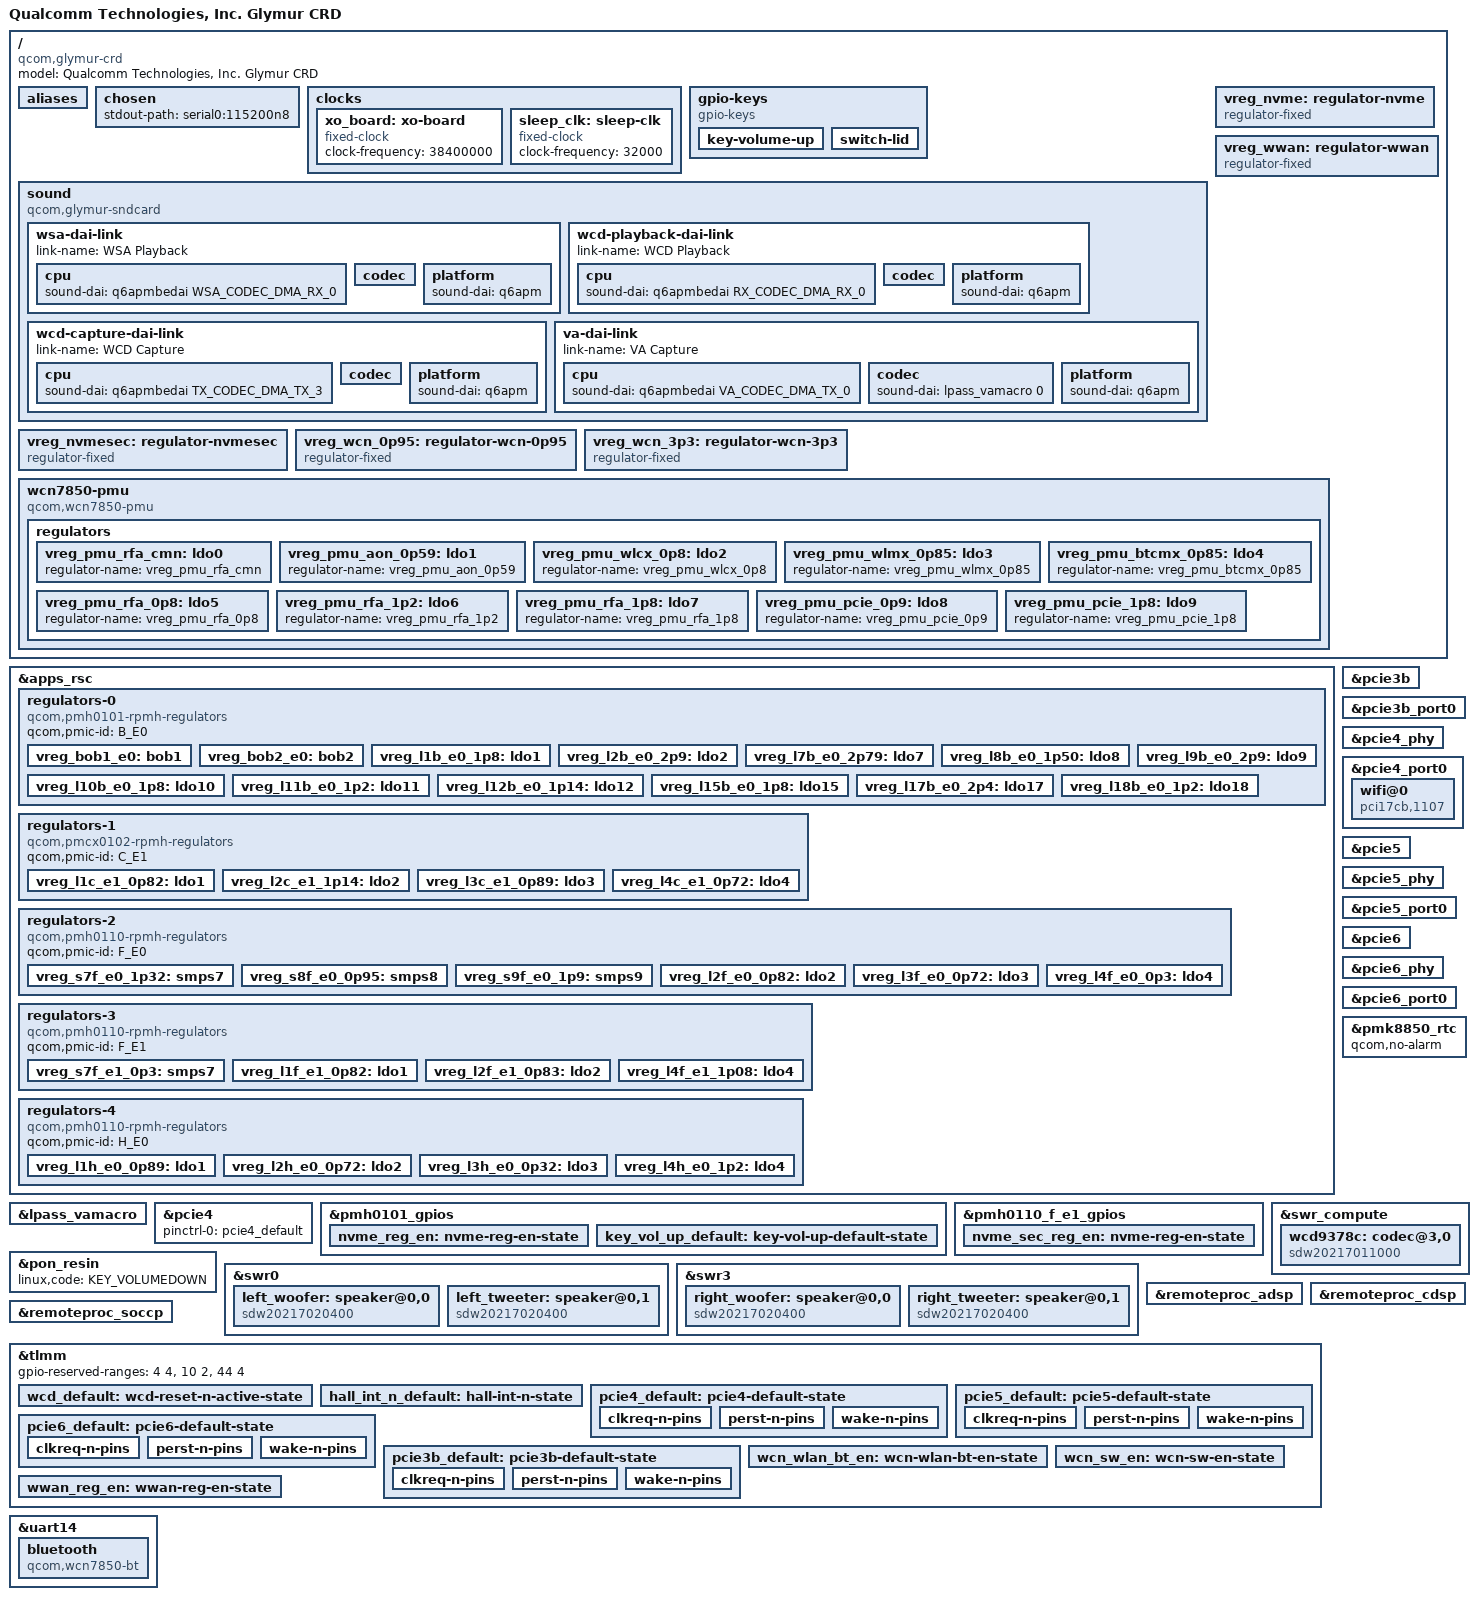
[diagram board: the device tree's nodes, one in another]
// SPDX-License-Identifier: BSD-3-Clause
/*
 * Copyright (c) Qualcomm Technologies, Inc. and/or its subsidiaries.
 */

#include "pmcx0102.dtsi"        /* SPMI0: SID-2/3 SPMI1: SID-2/3 */
#include "pmh0101.dtsi"         /* SPMI0: SID-1                  */
#include "pmh0110-glymur.dtsi"  /* SPMI0: SID-5/7 SPMI1: SID-5   */
#include "pmh0104-glymur.dtsi"  /* SPMI0: SID-8/9 SPMI1: SID-11  */
#include "pmk8850.dtsi"         /* SPMI0: SID-0                  */
#include "smb2370.dtsi"         /* SPMI2: SID-9/10/11            */

#include <dt-bindings/input/gpio-keys.h>

/ {
	model = "Qualcomm Technologies, Inc. Glymur CRD";
	compatible = "qcom,glymur-crd", "qcom,glymur";

	aliases {
		serial0 = &uart21;
		serial1 = &uart14;
		i2c0 = &i2c0;
		i2c1 = &i2c4;
		i2c2 = &i2c5;
		spi0 = &spi18;
	};

	chosen {
		stdout-path = "serial0:115200n8";
	};

	clocks {
		xo_board: xo-board {
			compatible = "fixed-clock";
			clock-frequency = <38400000>;
			#clock-cells = <0>;
		};

		sleep_clk: sleep-clk {
			compatible = "fixed-clock";
			clock-frequency = <32000>;
			#clock-cells = <0>;
		};
	};

	gpio-keys {
		compatible = "gpio-keys";

		pinctrl-0 = <&key_vol_up_default>, <&hall_int_n_default>;
		pinctrl-names = "default";

		key-volume-up {
			label = "Volume Up";
			linux,code = <KEY_VOLUMEUP>;
			gpios = <&pmh0101_gpios 6 GPIO_ACTIVE_LOW>;
			debounce-interval = <15>;
			linux,can-disable;
			wakeup-source;
		};

		switch-lid {
			label = "lid";
			gpios = <&tlmm 92 GPIO_ACTIVE_LOW>;
			linux,input-type = <EV_SW>;
			linux,code = <SW_LID>;
			wakeup-source;
			wakeup-event-action = <EV_ACT_DEASSERTED>;
		};
	};

	sound {
		compatible = "qcom,glymur-sndcard";
		model = "GLYMUR-CRD";
		audio-routing = "WooferLeft IN", "WSA WSA_SPK1 OUT",
				"TweeterLeft IN", "WSA WSA_SPK2 OUT",
				"WooferRight IN", "WSA2 WSA_SPK1 OUT",
				"TweeterRight IN", "WSA2 WSA_SPK2 OUT",
				"VA DMIC0", "vdd-micb",
				"VA DMIC1", "vdd-micb",
				"VA DMIC2", "vdd-micb",
				"VA DMIC3", "vdd-micb",
				"IT 41 Playback", "HPHL_OUT",
				"IT 41 Playback", "HPHR_OUT",
				/*
				 * Bridge the TX macro SoundWire input to the
				 * WCD9378 capture output terminal (OT 36, DP2)
				 * so DAPM completes the codec->macro capture
				 * path.  Without this the macro powers its
				 * decimator but no data is pulled from the codec.
				 */
				"TX SWR_INPUT1", "OT 36 Capture";

		wsa-dai-link {
			link-name = "WSA Playback";

			cpu {
				sound-dai = <&q6apmbedai WSA_CODEC_DMA_RX_0>;
			};

			codec {
				sound-dai = <&left_woofer>, <&left_tweeter>,
					    <&swr0 0>, <&lpass_wsamacro 0>,
					    <&right_woofer>, <&right_tweeter>,
					    <&swr3 0>, <&lpass_wsa2macro 0>;
			};

			platform {
				sound-dai = <&q6apm>;
			};
		};
		/*
		 * Compute mode: swr_compute is the single multi-lane SoundWire
		 * master; ASoC needs its master DAI in the codec cell so port
		 * setup and stream_add_master are driven for both banks.
		 *   swr_compute pin 0 = dout (playback)
		 *   swr_compute pin 1 = din  (capture)
		 */
		wcd-playback-dai-link {
			link-name = "WCD Playback";

			cpu {
				sound-dai = <&q6apmbedai RX_CODEC_DMA_RX_0>;
			};

			codec {
				sound-dai = <&wcd9378c 0>, <&swr_compute 0>, <&lpass_rxmacro 0>;
			};

			platform {
				sound-dai = <&q6apm>;
			};
		};

		wcd-capture-dai-link {
			link-name = "WCD Capture";

			cpu {
				sound-dai = <&q6apmbedai TX_CODEC_DMA_TX_3>;
			};

			codec {
				sound-dai = <&wcd9378c 18>, <&swr_compute 1>, <&lpass_txmacro 0>;
			};

			platform {
				sound-dai = <&q6apm>;
			};
		};

		va-dai-link {
			link-name = "VA Capture";

			cpu {
				sound-dai = <&q6apmbedai VA_CODEC_DMA_TX_0>;
			};

			codec {
				sound-dai = <&lpass_vamacro 0>;
			};

			platform {
				sound-dai = <&q6apm>;
			};
		};
	};

	vreg_nvme: regulator-nvme {
		compatible = "regulator-fixed";

		regulator-name = "VREG_NVME_3P3";
		regulator-min-microvolt = <3300000>;
		regulator-max-microvolt = <3300000>;

		gpio = <&pmh0101_gpios 14 GPIO_ACTIVE_HIGH>;
		enable-active-high;

		pinctrl-0 = <&nvme_reg_en>;
		pinctrl-names = "default";

		regulator-boot-on;
	};

	vreg_nvmesec: regulator-nvmesec {
		compatible = "regulator-fixed";

		regulator-name = "VREG_NVME_SEC_3P3";
		regulator-min-microvolt = <3300000>;
		regulator-max-microvolt = <3300000>;

		gpio = <&pmh0110_f_e1_gpios 14 GPIO_ACTIVE_HIGH>;
		enable-active-high;

		pinctrl-0 = <&nvme_sec_reg_en>;
		pinctrl-names = "default";

		regulator-boot-on;
	};

	vreg_wcn_0p95: regulator-wcn-0p95 {
		compatible = "regulator-fixed";

		regulator-name = "VREG_WCN_0P95";
		regulator-min-microvolt = <950000>;
		regulator-max-microvolt = <950000>;

		vin-supply = <&vreg_wcn_3p3>;
	};

	vreg_wcn_3p3: regulator-wcn-3p3 {
		compatible = "regulator-fixed";

		regulator-name = "VREG_WCN_3P3";
		regulator-min-microvolt = <3300000>;
		regulator-max-microvolt = <3300000>;

		gpio = <&tlmm 94 GPIO_ACTIVE_HIGH>;
		enable-active-high;

		pinctrl-0 = <&wcn_sw_en>;
		pinctrl-names = "default";

		regulator-boot-on;
	};

	vreg_wwan: regulator-wwan {
		compatible = "regulator-fixed";

		regulator-name = "VREG_WWAN_3P3";
		regulator-min-microvolt = <3300000>;
		regulator-max-microvolt = <3300000>;

		gpio = <&tlmm 246 GPIO_ACTIVE_HIGH>;
		enable-active-high;

		pinctrl-0 = <&wwan_reg_en>;
		pinctrl-names = "default";
	};

	wcn7850-pmu {
		compatible = "qcom,wcn7850-pmu";

		vdd-supply = <&vreg_wcn_0p95>;
		vddio-supply = <&vreg_l15b_e0_1p8>;
		vddaon-supply = <&vreg_l15b_e0_1p8>;
		vdddig-supply = <&vreg_l15b_e0_1p8>;
		vddrfa1p2-supply = <&vreg_l15b_e0_1p8>;
		vddrfa1p8-supply = <&vreg_l15b_e0_1p8>;

		wlan-enable-gpios = <&tlmm 117 GPIO_ACTIVE_HIGH>;
		bt-enable-gpios = <&tlmm 116 GPIO_ACTIVE_HIGH>;

		pinctrl-0 = <&wcn_wlan_bt_en>;
		pinctrl-names = "default";

		regulators {
			vreg_pmu_rfa_cmn: ldo0 {
				regulator-name = "vreg_pmu_rfa_cmn";
			};

			vreg_pmu_aon_0p59: ldo1 {
				regulator-name = "vreg_pmu_aon_0p59";
			};

			vreg_pmu_wlcx_0p8: ldo2 {
				regulator-name = "vreg_pmu_wlcx_0p8";
			};

			vreg_pmu_wlmx_0p85: ldo3 {
				regulator-name = "vreg_pmu_wlmx_0p85";
			};

			vreg_pmu_btcmx_0p85: ldo4 {
				regulator-name = "vreg_pmu_btcmx_0p85";
			};

			vreg_pmu_rfa_0p8: ldo5 {
				regulator-name = "vreg_pmu_rfa_0p8";
			};

			vreg_pmu_rfa_1p2: ldo6 {
				regulator-name = "vreg_pmu_rfa_1p2";
			};

			vreg_pmu_rfa_1p8: ldo7 {
				regulator-name = "vreg_pmu_rfa_1p8";
			};

			vreg_pmu_pcie_0p9: ldo8 {
				regulator-name = "vreg_pmu_pcie_0p9";
			};

			vreg_pmu_pcie_1p8: ldo9 {
				regulator-name = "vreg_pmu_pcie_1p8";
			};
		};
	};
};

&apps_rsc {
	regulators-0 {
		compatible = "qcom,pmh0101-rpmh-regulators";
		qcom,pmic-id = "B_E0";

		vreg_bob1_e0: bob1 {
			regulator-name = "vreg_bob1_e0";
			regulator-min-microvolt = <2200000>;
			regulator-max-microvolt = <4224000>;
			regulator-initial-mode = <RPMH_REGULATOR_MODE_AUTO>;
		};

		vreg_bob2_e0: bob2 {
			regulator-name = "vreg_bob2_e0";
			regulator-min-microvolt = <2540000>;
			regulator-max-microvolt = <3600000>;
			regulator-initial-mode = <RPMH_REGULATOR_MODE_AUTO>;
		};

		vreg_l1b_e0_1p8: ldo1 {
			regulator-name = "vreg_l1b_e0_1p8";
			regulator-min-microvolt = <1800000>;
			regulator-max-microvolt = <1800000>;
			regulator-initial-mode = <RPMH_REGULATOR_MODE_HPM>;
		};

		vreg_l2b_e0_2p9: ldo2 {
			regulator-name = "vreg_l2b_e0_2p9";
			regulator-min-microvolt = <1804000>;
			regulator-max-microvolt = <2904000>;
			regulator-initial-mode = <RPMH_REGULATOR_MODE_HPM>;
		};

		vreg_l7b_e0_2p79: ldo7 {
			regulator-name = "vreg_l7b_e0_2p79";
			regulator-min-microvolt = <2790000>;
			regulator-max-microvolt = <2792000>;
			regulator-initial-mode = <RPMH_REGULATOR_MODE_HPM>;
		};

		vreg_l8b_e0_1p50: ldo8 {
			regulator-name = "vreg_l8b_e0_1p50";
			regulator-min-microvolt = <1504000>;
			regulator-max-microvolt = <1504000>;
			regulator-initial-mode = <RPMH_REGULATOR_MODE_HPM>;
		};

		vreg_l9b_e0_2p9: ldo9 {
			regulator-name = "vreg_l9b_e0_2p9";
			regulator-min-microvolt = <2960000>;
			regulator-max-microvolt = <2960000>;
			regulator-initial-mode = <RPMH_REGULATOR_MODE_HPM>;
		};

		vreg_l10b_e0_1p8: ldo10 {
			regulator-name = "vreg_l10b_e0_1p8";
			regulator-min-microvolt = <1800000>;
			regulator-max-microvolt = <1800000>;
			regulator-initial-mode = <RPMH_REGULATOR_MODE_HPM>;
		};

		vreg_l11b_e0_1p2: ldo11 {
			regulator-name = "vreg_l11b_e0_1p2";
			regulator-min-microvolt = <1200000>;
			regulator-max-microvolt = <1200000>;
			regulator-initial-mode = <RPMH_REGULATOR_MODE_HPM>;
		};

		vreg_l12b_e0_1p14: ldo12 {
			regulator-name = "vreg_l12b_e0_1p14";
			regulator-min-microvolt = <1144000>;
			regulator-max-microvolt = <1144000>;
			regulator-initial-mode = <RPMH_REGULATOR_MODE_HPM>;
		};

		vreg_l15b_e0_1p8: ldo15 {
			regulator-name = "vreg_l15b_e0_1p8";
			regulator-min-microvolt = <1800000>;
			regulator-max-microvolt = <1800000>;
			regulator-initial-mode = <RPMH_REGULATOR_MODE_HPM>;
		};

		vreg_l17b_e0_2p4: ldo17 {
			regulator-name = "vreg_l17b_e0_2p4";
			regulator-min-microvolt = <2400000>;
			regulator-max-microvolt = <2700000>;
			regulator-initial-mode = <RPMH_REGULATOR_MODE_HPM>;
		};

		vreg_l18b_e0_1p2: ldo18 {
			regulator-name = "vreg_l18b_e0_1p2";
			regulator-min-microvolt = <1200000>;
			regulator-max-microvolt = <1200000>;
			regulator-initial-mode = <RPMH_REGULATOR_MODE_HPM>;
		};
	};

	regulators-1 {
		compatible = "qcom,pmcx0102-rpmh-regulators";
		qcom,pmic-id = "C_E1";

		vreg_l1c_e1_0p82: ldo1 {
			regulator-name = "vreg_l1c_e1_0p82";
			regulator-min-microvolt = <832000>;
			regulator-max-microvolt = <832000>;
			regulator-initial-mode = <RPMH_REGULATOR_MODE_HPM>;
		};

		vreg_l2c_e1_1p14: ldo2 {
			regulator-name = "vreg_l2c_e1_1p14";
			regulator-min-microvolt = <1144000>;
			regulator-max-microvolt = <1144000>;
			regulator-initial-mode = <RPMH_REGULATOR_MODE_HPM>;
		};

		vreg_l3c_e1_0p89: ldo3 {
			regulator-name = "vreg_l3c_e1_0p89";
			regulator-min-microvolt = <890000>;
			regulator-max-microvolt = <980000>;
			regulator-initial-mode = <RPMH_REGULATOR_MODE_HPM>;
		};

		vreg_l4c_e1_0p72: ldo4 {
			regulator-name = "vreg_l4c_e1_0p72";
			regulator-min-microvolt = <720000>;
			regulator-max-microvolt = <720000>;
			regulator-initial-mode = <RPMH_REGULATOR_MODE_HPM>;
		};
	};

	regulators-2 {
		compatible = "qcom,pmh0110-rpmh-regulators";
		qcom,pmic-id = "F_E0";

		vreg_s7f_e0_1p32: smps7 {
			regulator-name = "vreg_s7f_e0_1p32";
			regulator-min-microvolt = <1320000>;
			regulator-max-microvolt = <1352000>;
			regulator-initial-mode = <RPMH_REGULATOR_MODE_HPM>;
		};

		vreg_s8f_e0_0p95: smps8 {
			regulator-name = "vreg_s8f_e0_0p95";
			regulator-min-microvolt = <952000>;
			regulator-max-microvolt = <1200000>;
			regulator-initial-mode = <RPMH_REGULATOR_MODE_HPM>;
		};

		vreg_s9f_e0_1p9: smps9 {
			regulator-name = "vreg_s9f_e0_1p9";
			regulator-min-microvolt = <1900000>;
			regulator-max-microvolt = <2000000>;
			regulator-initial-mode = <RPMH_REGULATOR_MODE_HPM>;
		};

		vreg_l2f_e0_0p82: ldo2 {
			regulator-name = "vreg_l2f_e0_0p82";
			regulator-min-microvolt = <832000>;
			regulator-max-microvolt = <832000>;
			regulator-initial-mode = <RPMH_REGULATOR_MODE_HPM>;
		};

		vreg_l3f_e0_0p72: ldo3 {
			regulator-name = "vreg_l3f_e0_0p72";
			regulator-min-microvolt = <720000>;
			regulator-max-microvolt = <720000>;
			regulator-initial-mode = <RPMH_REGULATOR_MODE_HPM>;
		};

		vreg_l4f_e0_0p3: ldo4 {
			regulator-name = "vreg_l4f_e0_0p3";
			regulator-min-microvolt = <1080000>;
			regulator-max-microvolt = <1200000>;
			regulator-initial-mode = <RPMH_REGULATOR_MODE_HPM>;
		};
	};

	regulators-3 {
		compatible = "qcom,pmh0110-rpmh-regulators";
		qcom,pmic-id = "F_E1";

		vreg_s7f_e1_0p3: smps7 {
			regulator-name = "vreg_s7f_e1_0p3";
			regulator-min-microvolt = <300000>;
			regulator-max-microvolt = <1200000>;
			regulator-initial-mode = <RPMH_REGULATOR_MODE_HPM>;
		};

		vreg_l1f_e1_0p82: ldo1 {
			regulator-name = "vreg_l1f_e1_0p82";
			regulator-min-microvolt = <832000>;
			regulator-max-microvolt = <832000>;
			regulator-initial-mode = <RPMH_REGULATOR_MODE_HPM>;
		};

		vreg_l2f_e1_0p83: ldo2 {
			regulator-name = "vreg_l2f_e1_0p83";
			regulator-min-microvolt = <832000>;
			regulator-max-microvolt = <832000>;
			regulator-initial-mode = <RPMH_REGULATOR_MODE_HPM>;
		};

		vreg_l4f_e1_1p08: ldo4 {
			regulator-name = "vreg_l4f_e1_1p08";
			regulator-min-microvolt = <1080000>;
			regulator-max-microvolt = <1320000>;
			regulator-initial-mode = <RPMH_REGULATOR_MODE_HPM>;
		};
	};

	regulators-4 {
		compatible = "qcom,pmh0110-rpmh-regulators";
		qcom,pmic-id = "H_E0";

		vreg_l1h_e0_0p89: ldo1 {
			regulator-name = "vreg_l1h_e0_0p89";
			regulator-min-microvolt = <832000>;
			regulator-max-microvolt = <832000>;
			regulator-initial-mode = <RPMH_REGULATOR_MODE_HPM>;
		};

		vreg_l2h_e0_0p72: ldo2 {
			regulator-name = "vreg_l2h_e0_0p72";
			regulator-min-microvolt = <832000>;
			regulator-max-microvolt = <832000>;
			regulator-initial-mode = <RPMH_REGULATOR_MODE_HPM>;
		};

		vreg_l3h_e0_0p32: ldo3 {
			regulator-name = "vreg_l3h_e0_0p32";
			regulator-min-microvolt = <320000>;
			regulator-max-microvolt = <2000000>;
			regulator-initial-mode = <RPMH_REGULATOR_MODE_HPM>;
		};

		vreg_l4h_e0_1p2: ldo4 {
			regulator-name = "vreg_l4h_e0_1p2";
			regulator-min-microvolt = <1080000>;
			regulator-max-microvolt = <1320000>;
			regulator-initial-mode = <RPMH_REGULATOR_MODE_HPM>;
		};
	};
};

&lpass_vamacro {
	pinctrl-0 = <&dmic01_default>, <&dmic23_default>;
	pinctrl-names = "default";
	qcom,dmic-sample-rate = <4800000>;
};

&pcie3b {
	vddpe-3v3-supply = <&vreg_nvmesec>;

	pinctrl-0 = <&pcie3b_default>;
	pinctrl-names = "default";
};

&pcie3b_port0 {
	reset-gpios = <&tlmm 155 GPIO_ACTIVE_LOW>;
	wake-gpios = <&tlmm 157 GPIO_ACTIVE_LOW>;
};

&pcie4 {
	pinctrl-0 = <&pcie4_default>;
	pinctrl-names = "default";

	status = "okay";
};

&pcie4_phy {
	vdda-phy-supply = <&vreg_l1c_e1_0p82>;
	vdda-pll-supply = <&vreg_l4f_e1_1p08>;

	status = "okay";
};

&pcie4_port0 {
	reset-gpios = <&tlmm 146 GPIO_ACTIVE_LOW>;
	wake-gpios = <&tlmm 148 GPIO_ACTIVE_LOW>;

	wifi@0 {
		compatible = "pci17cb,1107";
		reg = <0x10000 0x0 0x0 0x0 0x0>;

		vddaon-supply = <&vreg_pmu_aon_0p59>;
		vddwlcx-supply = <&vreg_pmu_wlcx_0p8>;
		vddwlmx-supply = <&vreg_pmu_wlmx_0p85>;
		vddrfacmn-supply = <&vreg_pmu_rfa_cmn>;
		vddrfa0p8-supply = <&vreg_pmu_rfa_0p8>;
		vddrfa1p2-supply = <&vreg_pmu_rfa_1p2>;
		vddrfa1p8-supply = <&vreg_pmu_rfa_1p8>;
		vddpcie0p9-supply = <&vreg_pmu_pcie_0p9>;
		vddpcie1p8-supply = <&vreg_pmu_pcie_1p8>;
	};
};

&pcie5 {
	vddpe-3v3-supply = <&vreg_nvme>;

	pinctrl-0 = <&pcie5_default>;
	pinctrl-names = "default";

	status = "okay";
};

&pcie5_phy {
	vdda-phy-supply = <&vreg_l2f_e0_0p82>;
	vdda-pll-supply = <&vreg_l4h_e0_1p2>;

	status = "okay";
};

&pcie5_port0 {
	reset-gpios = <&tlmm 152 GPIO_ACTIVE_LOW>;
	wake-gpios = <&tlmm 154 GPIO_ACTIVE_LOW>;
};

&pcie6 {
	vddpe-3v3-supply = <&vreg_wwan>;

	pinctrl-0 = <&pcie6_default>;
	pinctrl-names = "default";

	status = "okay";
};

&pcie6_phy {
	vdda-phy-supply = <&vreg_l1c_e1_0p82>;
	vdda-pll-supply = <&vreg_l4f_e1_1p08>;

	status = "okay";
};

&pcie6_port0 {
	reset-gpios = <&tlmm 149 GPIO_ACTIVE_LOW>;
	wake-gpios = <&tlmm 151 GPIO_ACTIVE_LOW>;
};

&pmh0101_gpios {
	nvme_reg_en: nvme-reg-en-state {
		pins = "gpio14";
		function = "normal";
		bias-disable;
	};

	key_vol_up_default: key-vol-up-default-state {
		pins = "gpio6";
		function = "normal";
		output-disable;
		bias-pull-up;
	};
};

&pmh0110_f_e1_gpios {
	nvme_sec_reg_en: nvme-reg-en-state {
		pins = "gpio14";
		function = "normal";
		bias-disable;
	};
};

&pmk8850_rtc {
	qcom,no-alarm;
};

&pon_resin {
	linux,code = <KEY_VOLUMEDOWN>;
	status = "okay";
};

&swr0 {
	status = "okay";

	/* WSA8845, Left Woofer */
	left_woofer: speaker@0,0 {
		compatible = "sdw20217020400";
		reg = <0 0>;
		reset-gpios = <&lpass_tlmm 12 GPIO_ACTIVE_LOW>;
		#sound-dai-cells = <0>;
		sound-name-prefix = "WooferLeft";
		vdd-1p8-supply = <&vreg_l15b_e0_1p8>;
		vdd-io-supply = <&vreg_l18b_e0_1p2>;
		qcom,port-mapping = <1 2 3 7 12 14>;
	};

	/* WSA8845, Left Tweeter */
	left_tweeter: speaker@0,1 {
		compatible = "sdw20217020400";
		reg = <0 1>;
		reset-gpios = <&lpass_tlmm 12 GPIO_ACTIVE_LOW>;
		#sound-dai-cells = <0>;
		sound-name-prefix = "TweeterLeft";
		vdd-1p8-supply = <&vreg_l15b_e0_1p8>;
		vdd-io-supply = <&vreg_l18b_e0_1p2>;
		qcom,port-mapping = <4 5 6 7 13 15>;
	};
};
/*
 * Glymur runs WCD9378 in SDCA compute mode: one slave on one logical
 * SoundWire bus that aggregates the TX and RX SWR master IPs.  Use the
 * multi-lane controller (swr_compute) instead of the per-IP swr1/swr2,
 * which therefore stay disabled (default).
 */
&swr_compute {
	status = "okay";

	wcd9378c: codec@3,0 {
		compatible = "sdw20217011000";
		reg = <0 3>;

		pinctrl-names = "default";
		pinctrl-0 = <&wcd_default>;

		reset-gpios = <&tlmm 191 GPIO_ACTIVE_LOW>;

		vdd-buck-supply = <&vreg_l15b_e0_1p8>;
		vdd-rxtx-supply = <&vreg_l15b_e0_1p8>;
		vdd-io-supply = <&vreg_l18b_e0_1p2>;
		vdd-mic-bias-supply = <&vreg_bob1_e0>;

		#sound-dai-cells = <1>;
		/* DP1..DP8 → unified bus ports (lanes select the bank).
		 * Ports 2 (DP2 TX), 6/7/8 (DP6/7/8 RX) drive real traffic. */
		qcom,port-mapping = <2 2 3 4 5 6 7 8>;
	};
};


&swr3 {
	status = "okay";

	/* WSA8845, Right Woofer */
	right_woofer: speaker@0,0 {
		compatible = "sdw20217020400";
		reg = <0 0>;
		reset-gpios = <&lpass_tlmm 13 GPIO_ACTIVE_LOW>;
		#sound-dai-cells = <0>;
		sound-name-prefix = "WooferRight";
		vdd-1p8-supply = <&vreg_l15b_e0_1p8>;
		vdd-io-supply = <&vreg_l18b_e0_1p2>;
		qcom,port-mapping = <1 2 3 7 12 14>;
	};

	/* WSA8845, Right Tweeter */
	right_tweeter: speaker@0,1 {
		compatible = "sdw20217020400";
		reg = <0 1>;
		reset-gpios = <&lpass_tlmm 13 GPIO_ACTIVE_LOW>;
		#sound-dai-cells = <0>;
		sound-name-prefix = "TweeterRight";
		vdd-1p8-supply = <&vreg_l15b_e0_1p8>;
		vdd-io-supply = <&vreg_l18b_e0_1p2>;
		qcom,port-mapping = <4 5 6 7 13 15>;
	};
};

&remoteproc_adsp {
	firmware-name = "qcom/glymur/adsp.mbn",
			"qcom/glymur/adsp_dtb.mbn";

	status = "okay";
};

&remoteproc_cdsp {
	firmware-name = "qcom/glymur/cdsp.mbn",
			"qcom/glymur/cdsp_dtb.mbn";

	status = "okay";
};

&remoteproc_soccp {
	status = "okay";
};

&tlmm {
	gpio-reserved-ranges = <4 4>, /* EC TZ Secure I3C */
			       <10 2>, /* OOB UART */
			       <44 4>; /* Security SPI (TPM) */
	wcd_default: wcd-reset-n-active-state {
		pins = "gpio191";
		function = "gpio";
		drive-strength = <16>;
		bias-disable;
		output-low;
	};


	hall_int_n_default: hall-int-n-state {
		pins = "gpio92";
		function = "gpio";
		bias-disable;
	};

	pcie4_default: pcie4-default-state {
		clkreq-n-pins {
			pins = "gpio147";
			function = "pcie4_clk_req_n";
			drive-strength = <2>;
			bias-pull-up;
		};

		perst-n-pins {
			pins = "gpio146";
			function = "gpio";
			drive-strength = <2>;
			bias-disable;
		};

		wake-n-pins {
			pins = "gpio148";
			function = "gpio";
			drive-strength = <2>;
			bias-pull-up;
		};
	};

	pcie5_default: pcie5-default-state {
		clkreq-n-pins {
			pins = "gpio153";
			function = "pcie5_clk_req_n";
			drive-strength = <2>;
			bias-pull-up;
		};

		perst-n-pins {
			pins = "gpio152";
			function = "gpio";
			drive-strength = <2>;
			bias-disable;
		};

		wake-n-pins {
			pins = "gpio154";
			function = "gpio";
			drive-strength = <2>;
			bias-pull-up;
		};
	};

	pcie6_default: pcie6-default-state {
		clkreq-n-pins {
			pins = "gpio150";
			function = "pcie6_clk_req_n";
			drive-strength = <2>;
			bias-pull-up;
		};

		perst-n-pins {
			pins = "gpio149";
			function = "gpio";
			drive-strength = <2>;
			bias-disable;
		};

		wake-n-pins {
			pins = "gpio151";
			function = "gpio";
			drive-strength = <2>;
			bias-pull-up;
		};
	};

	pcie3b_default: pcie3b-default-state {
		clkreq-n-pins {
			pins = "gpio156";
			function = "pcie3b_clk";
			drive-strength = <2>;
			bias-pull-up;
		};

		perst-n-pins {
			pins = "gpio155";
			function = "gpio";
			drive-strength = <2>;
			bias-disable;
		};

		wake-n-pins {
			pins = "gpio157";
			function = "gpio";
			drive-strength = <2>;
			bias-pull-up;
		};
	};

	wcn_wlan_bt_en: wcn-wlan-bt-en-state {
		pins = "gpio116", "gpio117";
		function = "gpio";
		drive-strength = <2>;
		bias-disable;
	};

	wcn_sw_en: wcn-sw-en-state {
		pins = "gpio94";
		function = "gpio";
		drive-strength = <2>;
		bias-disable;
	};

	wwan_reg_en: wwan-reg-en-state {
		pins = "gpio246";
		function = "gpio";
		drive-strength = <2>;
		bias-disable;
	};
};

&uart14 {
	status = "okay";

	bluetooth {
		compatible = "qcom,wcn7850-bt";
		max-speed = <3200000>;

		vddaon-supply = <&vreg_pmu_aon_0p59>;
		vddwlcx-supply = <&vreg_pmu_wlcx_0p8>;
		vddwlmx-supply = <&vreg_pmu_wlmx_0p85>;
		vddrfacmn-supply = <&vreg_pmu_rfa_cmn>;
		vddrfa0p8-supply = <&vreg_pmu_rfa_0p8>;
		vddrfa1p2-supply = <&vreg_pmu_rfa_1p2>;
		vddrfa1p8-supply = <&vreg_pmu_rfa_1p8>;
	};
};
